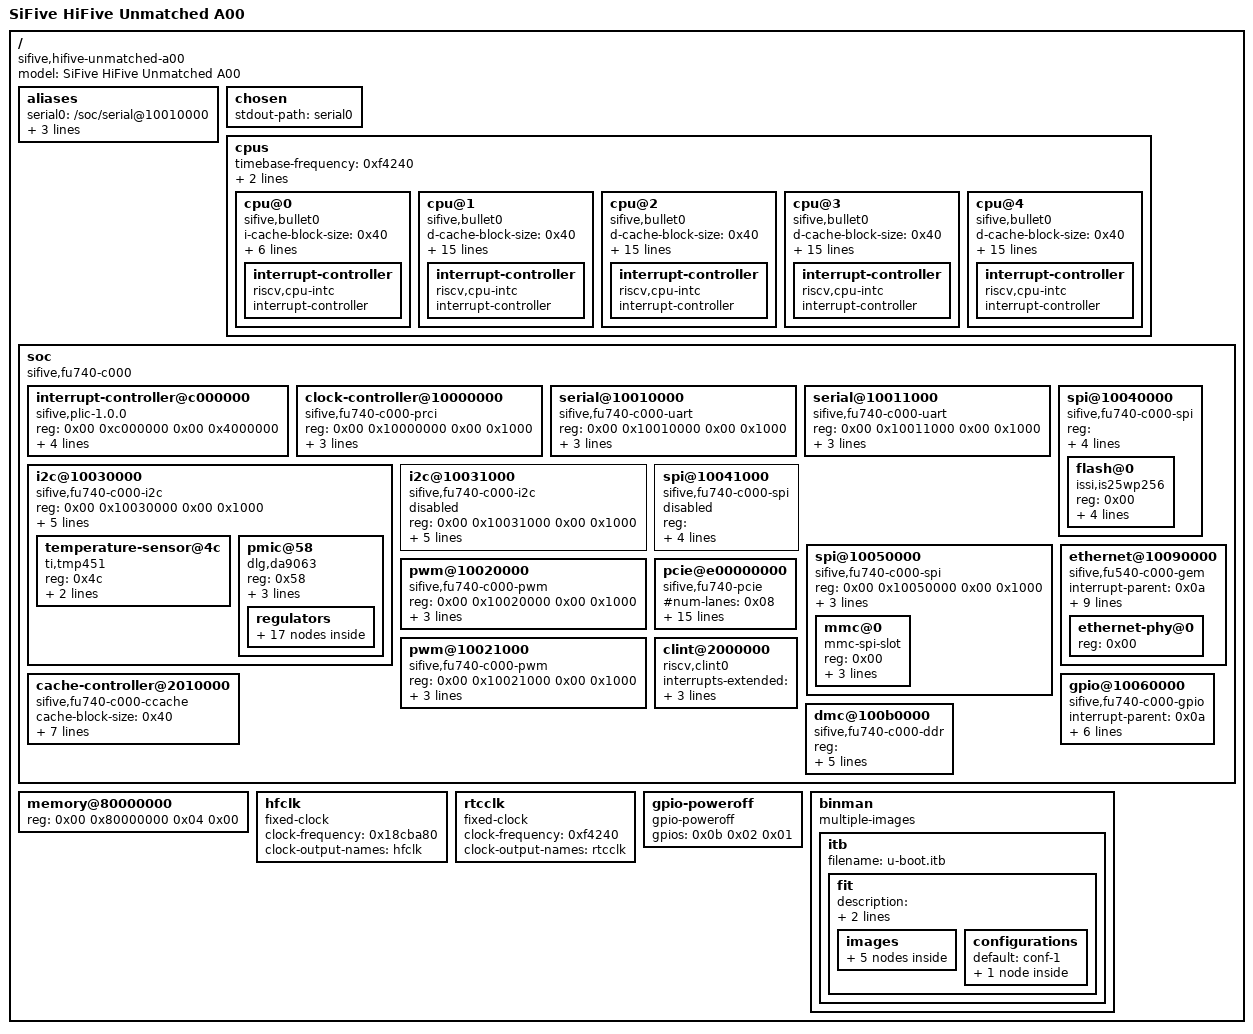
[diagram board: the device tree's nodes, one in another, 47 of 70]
/dts-v1/;

/ {
	#address-cells = <0x02>;
	#size-cells = <0x02>;
	compatible = "sifive,hifive-unmatched-a00\0sifive,fu740-c000\0sifive,fu740";
	model = "SiFive HiFive Unmatched A00";

	aliases {
		serial0 = "/soc/serial@10010000";
		serial1 = "/soc/serial@10011000";
		ethernet0 = "/soc/ethernet@10090000";
		spi0 = "/soc/spi@10050000";
	};

	chosen {
		stdout-path = "serial0";
	};

	cpus {
		#address-cells = <0x01>;
		#size-cells = <0x00>;
		timebase-frequency = <0xf4240>;
		assigned-clocks = <0x01 0x00>;
		assigned-clock-rates = <0x47868c00>;
		u-boot,dm-spl;

		cpu@0 {
			compatible = "sifive,bullet0\0riscv";
			device_type = "cpu";
			i-cache-block-size = <0x40>;
			i-cache-sets = <0x80>;
			i-cache-size = <0x4000>;
			next-level-cache = <0x02>;
			reg = <0x00>;
			riscv,isa = "rv64imac";
			status = "okay";
			clocks = <0x01 0x00>;
			u-boot,dm-spl;

			interrupt-controller {
				#interrupt-cells = <0x01>;
				compatible = "riscv,cpu-intc";
				interrupt-controller;
				u-boot,dm-spl;
				phandle = <0x03>;
			};
		};

		cpu@1 {
			compatible = "sifive,bullet0\0riscv";
			d-cache-block-size = <0x40>;
			d-cache-sets = <0x40>;
			d-cache-size = <0x8000>;
			d-tlb-sets = <0x01>;
			d-tlb-size = <0x28>;
			device_type = "cpu";
			i-cache-block-size = <0x40>;
			i-cache-sets = <0x80>;
			i-cache-size = <0x8000>;
			i-tlb-sets = <0x01>;
			i-tlb-size = <0x28>;
			mmu-type = "riscv,sv39";
			next-level-cache = <0x02>;
			reg = <0x01>;
			riscv,isa = "rv64imafdc";
			tlb-split;
			clocks = <0x01 0x00>;
			u-boot,dm-spl;

			interrupt-controller {
				#interrupt-cells = <0x01>;
				compatible = "riscv,cpu-intc";
				interrupt-controller;
				u-boot,dm-spl;
				phandle = <0x04>;
			};
		};

		cpu@2 {
			compatible = "sifive,bullet0\0riscv";
			d-cache-block-size = <0x40>;
			d-cache-sets = <0x40>;
			d-cache-size = <0x8000>;
			d-tlb-sets = <0x01>;
			d-tlb-size = <0x28>;
			device_type = "cpu";
			i-cache-block-size = <0x40>;
			i-cache-sets = <0x80>;
			i-cache-size = <0x8000>;
			i-tlb-sets = <0x01>;
			i-tlb-size = <0x28>;
			mmu-type = "riscv,sv39";
			next-level-cache = <0x02>;
			reg = <0x02>;
			riscv,isa = "rv64imafdc";
			tlb-split;
			clocks = <0x01 0x00>;
			u-boot,dm-spl;

			interrupt-controller {
				#interrupt-cells = <0x01>;
				compatible = "riscv,cpu-intc";
				interrupt-controller;
				u-boot,dm-spl;
				phandle = <0x05>;
			};
		};

		cpu@3 {
			compatible = "sifive,bullet0\0riscv";
			d-cache-block-size = <0x40>;
			d-cache-sets = <0x40>;
			d-cache-size = <0x8000>;
			d-tlb-sets = <0x01>;
			d-tlb-size = <0x28>;
			device_type = "cpu";
			i-cache-block-size = <0x40>;
			i-cache-sets = <0x80>;
			i-cache-size = <0x8000>;
			i-tlb-sets = <0x01>;
			i-tlb-size = <0x28>;
			mmu-type = "riscv,sv39";
			next-level-cache = <0x02>;
			reg = <0x03>;
			riscv,isa = "rv64imafdc";
			tlb-split;
			clocks = <0x01 0x00>;
			u-boot,dm-spl;

			interrupt-controller {
				#interrupt-cells = <0x01>;
				compatible = "riscv,cpu-intc";
				interrupt-controller;
				u-boot,dm-spl;
				phandle = <0x06>;
			};
		};

		cpu@4 {
			compatible = "sifive,bullet0\0riscv";
			d-cache-block-size = <0x40>;
			d-cache-sets = <0x40>;
			d-cache-size = <0x8000>;
			d-tlb-sets = <0x01>;
			d-tlb-size = <0x28>;
			device_type = "cpu";
			i-cache-block-size = <0x40>;
			i-cache-sets = <0x80>;
			i-cache-size = <0x8000>;
			i-tlb-sets = <0x01>;
			i-tlb-size = <0x28>;
			mmu-type = "riscv,sv39";
			next-level-cache = <0x02>;
			reg = <0x04>;
			riscv,isa = "rv64imafdc";
			tlb-split;
			clocks = <0x01 0x00>;
			u-boot,dm-spl;

			interrupt-controller {
				#interrupt-cells = <0x01>;
				compatible = "riscv,cpu-intc";
				interrupt-controller;
				u-boot,dm-spl;
				phandle = <0x07>;
			};
		};
	};

	soc {
		#address-cells = <0x02>;
		#size-cells = <0x02>;
		compatible = "sifive,fu740-c000\0sifive,fu740\0simple-bus";
		ranges;
		u-boot,dm-spl;

		interrupt-controller@c000000 {
			#interrupt-cells = <0x01>;
			compatible = "sifive,plic-1.0.0";
			reg = <0x00 0xc000000 0x00 0x4000000>;
			riscv,ndev = <0x45>;
			interrupt-controller;
			interrupts-extended = <0x03 0xffffffff 0x04 0xffffffff 0x04 0x09 0x05 0xffffffff 0x05 0x09 0x06 0xffffffff 0x06 0x09 0x07 0xffffffff 0x07 0x09>;
			phandle = <0x0a>;
		};

		clock-controller@10000000 {
			compatible = "sifive,fu740-c000-prci";
			reg = <0x00 0x10000000 0x00 0x1000>;
			clocks = <0x08 0x09>;
			#clock-cells = <0x01>;
			#reset-cells = <0x01>;
			resets = <0x01 0x00 0x01 0x01 0x01 0x02 0x01 0x03 0x01 0x05 0x01 0x06>;
			reset-names = "ddr_ctrl\0ddr_axi\0ddr_ahb\0ddr_phy\0gemgxl_reset\0cltx_reset";
			u-boot,dm-spl;
			phandle = <0x01>;
		};

		serial@10010000 {
			compatible = "sifive,fu740-c000-uart\0sifive,uart0";
			reg = <0x00 0x10010000 0x00 0x1000>;
			interrupt-parent = <0x0a>;
			interrupts = <0x27>;
			clocks = <0x01 0x07>;
			status = "okay";
			u-boot,dm-spl;
		};

		serial@10011000 {
			compatible = "sifive,fu740-c000-uart\0sifive,uart0";
			reg = <0x00 0x10011000 0x00 0x1000>;
			interrupt-parent = <0x0a>;
			interrupts = <0x28>;
			clocks = <0x01 0x07>;
			status = "okay";
		};

		i2c@10030000 {
			compatible = "sifive,fu740-c000-i2c\0sifive,i2c0";
			reg = <0x00 0x10030000 0x00 0x1000>;
			interrupt-parent = <0x0a>;
			interrupts = <0x34>;
			clocks = <0x01 0x07>;
			reg-shift = <0x02>;
			reg-io-width = <0x01>;
			#address-cells = <0x01>;
			#size-cells = <0x00>;
			status = "okay";
			u-boot,dm-spl;

			temperature-sensor@4c {
				compatible = "ti,tmp451";
				reg = <0x4c>;
				interrupt-parent = <0x0b>;
				interrupts = <0x06 0x08>;
			};

			pmic@58 {
				compatible = "dlg,da9063";
				reg = <0x58>;
				interrupt-parent = <0x0b>;
				interrupts = <0x01 0x08>;
				interrupt-controller;

				regulators {

					bcore1 {
						regulator-min-microvolt = <0x100590>;
						regulator-max-microvolt = <0x100590>;
						regulator-min-microamp = <0x4c4b40>;
						regulator-max-microamp = <0x4c4b40>;
						regulator-always-on;
					};

					bcore2 {
						regulator-min-microvolt = <0x100590>;
						regulator-max-microvolt = <0x100590>;
						regulator-min-microamp = <0x4c4b40>;
						regulator-max-microamp = <0x4c4b40>;
						regulator-always-on;
					};

					bpro {
						regulator-min-microvolt = <0x1b7740>;
						regulator-max-microvolt = <0x1b7740>;
						regulator-min-microamp = <0x2625a0>;
						regulator-max-microamp = <0x2625a0>;
						regulator-always-on;
					};

					bperi {
						regulator-min-microvolt = <0x100590>;
						regulator-max-microvolt = <0x100590>;
						regulator-min-microamp = <0x16e360>;
						regulator-max-microamp = <0x16e360>;
						regulator-always-on;
					};

					bmem {
						regulator-min-microvolt = <0x124f80>;
						regulator-max-microvolt = <0x124f80>;
						regulator-min-microamp = <0x2dc6c0>;
						regulator-max-microamp = <0x2dc6c0>;
						regulator-always-on;
					};

					bio {
						regulator-min-microvolt = <0x124f80>;
						regulator-max-microvolt = <0x124f80>;
						regulator-min-microamp = <0x2dc6c0>;
						regulator-max-microamp = <0x2dc6c0>;
						regulator-always-on;
					};

					ldo1 {
						regulator-min-microvolt = <0x1b7740>;
						regulator-max-microvolt = <0x1b7740>;
						regulator-min-microamp = <0x186a0>;
						regulator-max-microamp = <0x186a0>;
						regulator-always-on;
					};

					ldo2 {
						regulator-min-microvolt = <0x1b7740>;
						regulator-max-microvolt = <0x1b7740>;
						regulator-min-microamp = <0x30d40>;
						regulator-max-microamp = <0x30d40>;
						regulator-always-on;
					};

					ldo3 {
						regulator-min-microvolt = <0x325aa0>;
						regulator-max-microvolt = <0x325aa0>;
						regulator-min-microamp = <0x30d40>;
						regulator-max-microamp = <0x30d40>;
						regulator-always-on;
					};

					ldo4 {
						regulator-min-microvolt = <0x2625a0>;
						regulator-max-microvolt = <0x2625a0>;
						regulator-min-microamp = <0x30d40>;
						regulator-max-microamp = <0x30d40>;
						regulator-always-on;
					};

					ldo5 {
						regulator-min-microvolt = <0x325aa0>;
						regulator-max-microvolt = <0x325aa0>;
						regulator-min-microamp = <0x186a0>;
						regulator-max-microamp = <0x186a0>;
						regulator-always-on;
					};

					ldo6 {
						regulator-min-microvolt = <0x1b7740>;
						regulator-max-microvolt = <0x1b7740>;
						regulator-min-microamp = <0x30d40>;
						regulator-max-microamp = <0x30d40>;
						regulator-always-on;
					};

					ldo7 {
						regulator-min-microvolt = <0x325aa0>;
						regulator-max-microvolt = <0x325aa0>;
						regulator-min-microamp = <0x30d40>;
						regulator-max-microamp = <0x30d40>;
						regulator-always-on;
					};

					ldo8 {
						regulator-min-microvolt = <0x325aa0>;
						regulator-max-microvolt = <0x325aa0>;
						regulator-min-microamp = <0x30d40>;
						regulator-max-microamp = <0x30d40>;
						regulator-always-on;
					};

					ldo9 {
						regulator-min-microvolt = <0x100590>;
						regulator-max-microvolt = <0x100590>;
						regulator-min-microamp = <0x30d40>;
						regulator-max-microamp = <0x30d40>;
					};

					ldo10 {
						regulator-min-microvolt = <0xf4240>;
						regulator-max-microvolt = <0xf4240>;
						regulator-min-microamp = <0x493e0>;
						regulator-max-microamp = <0x493e0>;
					};

					ldo11 {
						regulator-min-microvolt = <0x2625a0>;
						regulator-max-microvolt = <0x2625a0>;
						regulator-min-microamp = <0x493e0>;
						regulator-max-microamp = <0x493e0>;
						regulator-always-on;
					};
				};
			};
		};

		i2c@10031000 {
			compatible = "sifive,fu740-c000-i2c\0sifive,i2c0";
			reg = <0x00 0x10031000 0x00 0x1000>;
			interrupt-parent = <0x0a>;
			interrupts = <0x35>;
			clocks = <0x01 0x07>;
			reg-shift = <0x02>;
			reg-io-width = <0x01>;
			#address-cells = <0x01>;
			#size-cells = <0x00>;
			status = "disabled";
		};

		spi@10040000 {
			compatible = "sifive,fu740-c000-spi\0sifive,spi0";
			reg = <0x00 0x10040000 0x00 0x1000 0x00 0x20000000 0x00 0x10000000>;
			interrupt-parent = <0x0a>;
			interrupts = <0x29>;
			clocks = <0x01 0x07>;
			#address-cells = <0x01>;
			#size-cells = <0x00>;
			status = "okay";

			flash@0 {
				compatible = "issi,is25wp256\0jedec,spi-nor";
				reg = <0x00>;
				spi-max-frequency = <0x2faf080>;
				m25p,fast-read;
				spi-tx-bus-width = <0x04>;
				spi-rx-bus-width = <0x04>;
			};
		};

		spi@10041000 {
			compatible = "sifive,fu740-c000-spi\0sifive,spi0";
			reg = <0x00 0x10041000 0x00 0x1000 0x00 0x30000000 0x00 0x10000000>;
			interrupt-parent = <0x0a>;
			interrupts = <0x2a>;
			clocks = <0x01 0x07>;
			#address-cells = <0x01>;
			#size-cells = <0x00>;
			status = "disabled";
		};

		spi@10050000 {
			compatible = "sifive,fu740-c000-spi\0sifive,spi0";
			reg = <0x00 0x10050000 0x00 0x1000>;
			interrupt-parent = <0x0a>;
			interrupts = <0x2b>;
			clocks = <0x01 0x07>;
			#address-cells = <0x01>;
			#size-cells = <0x00>;
			status = "okay";
			u-boot,dm-spl;

			mmc@0 {
				compatible = "mmc-spi-slot";
				reg = <0x00>;
				spi-max-frequency = <0x1312d00>;
				voltage-ranges = <0xce4 0xce4>;
				disable-wp;
				u-boot,dm-spl;
			};
		};

		ethernet@10090000 {
			compatible = "sifive,fu540-c000-gem";
			interrupt-parent = <0x0a>;
			interrupts = <0x37>;
			reg = <0x00 0x10090000 0x00 0x2000 0x00 0x100a0000 0x00 0x1000>;
			local-mac-address = [00 00 00 00 00 00];
			clock-names = "pclk\0hclk";
			clocks = <0x01 0x02 0x01 0x02>;
			#address-cells = <0x01>;
			#size-cells = <0x00>;
			status = "okay";
			phy-mode = "gmii";
			phy-handle = <0x0c>;
			assigned-clocks = <0x01 0x02>;
			assigned-clock-rates = <0x7754188>;

			ethernet-phy@0 {
				reg = <0x00>;
				phandle = <0x0c>;
			};
		};

		pwm@10020000 {
			compatible = "sifive,fu740-c000-pwm\0sifive,pwm0";
			reg = <0x00 0x10020000 0x00 0x1000>;
			interrupt-parent = <0x0a>;
			interrupts = <0x2c 0x2d 0x2e 0x2f>;
			clocks = <0x01 0x07>;
			#pwm-cells = <0x03>;
			status = "okay";
		};

		pwm@10021000 {
			compatible = "sifive,fu740-c000-pwm\0sifive,pwm0";
			reg = <0x00 0x10021000 0x00 0x1000>;
			interrupt-parent = <0x0a>;
			interrupts = <0x30 0x31 0x32 0x33>;
			clocks = <0x01 0x07>;
			#pwm-cells = <0x03>;
			status = "okay";
		};

		cache-controller@2010000 {
			compatible = "sifive,fu740-c000-ccache\0cache";
			cache-block-size = <0x40>;
			cache-level = <0x02>;
			cache-sets = <0x800>;
			cache-size = <0x200000>;
			cache-unified;
			interrupt-parent = <0x0a>;
			interrupts = <0x13 0x15 0x16 0x14>;
			reg = <0x00 0x2010000 0x00 0x1000>;
			status = "okay";
			phandle = <0x02>;
		};

		gpio@10060000 {
			compatible = "sifive,fu740-c000-gpio\0sifive,gpio0";
			interrupt-parent = <0x0a>;
			interrupts = <0x17 0x18 0x19 0x1a 0x1b 0x1c 0x1d 0x1e 0x1f 0x20 0x21 0x22 0x23 0x24 0x25 0x26>;
			reg = <0x00 0x10060000 0x00 0x1000>;
			gpio-controller;
			#gpio-cells = <0x02>;
			interrupt-controller;
			#interrupt-cells = <0x02>;
			clocks = <0x01 0x07>;
			status = "okay";
			u-boot,dm-spl;
			phandle = <0x0b>;
		};

		pcie@e00000000 {
			#address-cells = <0x03>;
			#interrupt-cells = <0x01>;
			#num-lanes = <0x08>;
			#size-cells = <0x02>;
			compatible = "sifive,fu740-pcie";
			reg = <0x0e 0x00 0x01 0x00 0x0d 0xf0000000 0x00 0x10000000 0x00 0x100d0000 0x00 0x1000>;
			reg-names = "dbi\0config\0mgmt";
			device_type = "pci";
			dma-coherent;
			bus-range = <0x00 0xff>;
			ranges = <0x81000000 0x00 0x60080000 0x00 0x60080000 0x00 0x10000 0x82000000 0x00 0x60090000 0x00 0x60090000 0x00 0xff70000 0x82000000 0x00 0x70000000 0x00 0x70000000 0x00 0x1000000 0xc3000000 0x20 0x00 0x20 0x00 0x20 0x00>;
			num-lanes = <0x08>;
			interrupts = <0x38 0x39 0x3a 0x3b 0x3c 0x3d 0x3e 0x3f 0x40>;
			interrupt-names = "msi\0inta\0intb\0intc\0intd";
			interrupt-parent = <0x0a>;
			interrupt-map-mask = <0x00 0x00 0x00 0x07>;
			interrupt-map = <0x00 0x00 0x00 0x01 0x0a 0x39 0x00 0x00 0x00 0x02 0x0a 0x3a 0x00 0x00 0x00 0x03 0x0a 0x3b 0x00 0x00 0x00 0x04 0x0a 0x3c>;
			pwren-gpios = <0x0b 0x05 0x00>;
			reset-gpios = <0x0b 0x08 0x00>;
			clocks = <0x01 0x08>;
			clock-names = "pcieaux";
			resets = <0x01 0x04>;
			reset-names = "rst_n";
			status = "okay";
		};

		clint@2000000 {
			compatible = "riscv,clint0";
			interrupts-extended = <0x03 0x03 0x03 0x07 0x04 0x03 0x04 0x07 0x05 0x03 0x05 0x07 0x06 0x03 0x06 0x07 0x07 0x03 0x07 0x07>;
			reg = <0x00 0x2000000 0x00 0x10000>;
			u-boot,dm-spl;
			clocks = <0x09>;
		};

		dmc@100b0000 {
			compatible = "sifive,fu740-c000-ddr";
			reg = <0x00 0x100b0000 0x00 0x800 0x00 0x100b2000 0x00 0x2000 0x00 0x100b8000 0x00 0x1000>;
			clocks = <0x01 0x01>;
			clock-frequency = <0x37a1894c>;
			u-boot,dm-spl;
			sifive,ddr-params = <0xa00 0x00 0x00 0x00 0x00 0x00 0x0a 0x2d362 0x71073 0xa1c0255 0x1c1c0400 0x404c90b 0x2b050405 0xd0c081e 0x8090914 0xfde718 0x180a05 0x8b130d 0x1000118 0xd032001 0x00 0x101 0x00 0xa000000 0x00 0x1450100 0x1c36 0x05 0x170006 0x14e0400 0x3010000 0xa0e00 0x4030200 0x31f 0x70004 0x00 0x00 0x00 0x00 0x00 0x00 0x00 0x00 0x00 0x00 0x00 0x00 0x00 0x00 0x00 0x00 0x00 0x00 0x00 0x00 0x00 0x00 0x00 0x00 0x00 0x424 0x201 0x1008 0x00 0x200 0x800 0x481 0x400 0x424 0x201 0x1008 0x00 0x200 0x800 0x481 0x400 0x1010000 0x00 0x00 0x00 0x00 0x00 0x00 0x00 0x00 0x00 0x00 0x00 0x00 0x00 0x00 0x00 0x00 0x00 0x00 0x00 0x00 0x00 0x00 0x00 0x00 0x00 0x00 0x00 0x00 0x03 0x00 0x00 0x00 0x00 0x1000000 0x40000 0x800200 0x200 0x40 0x1000100 0xa000002 0x101ffff 0x1010101 0x1010101 0x10b 0xc03 0x00 0x00 0x00 0x00 0x30300 0x00 0x10101 0x00 0x00 0x00 0x00 0x00 0x00 0x00 0x00 0x00 0x00 0x00 0x00 0x00 0x00 0x00 0x00 0x00 0x00 0x00 0x00 0x00 0x00 0x00 0x00 0x00 0x00 0x00 0x00 0x00 0x00 0x00 0x00 0x2010102 0x108070d 0x5050300 0x4000503 0x00 0x00 0x00 0x00 0x280d0000 0x1000000 0x00 0x30001 0x00 0x00 0x00 0x00 0x00 0x00 0x00 0x00 0x1000000 0x01 0x100 0x10303 0x67676701 0x67676767 0x67676767 0x67676767 0x67676767 0x67676767 0x67676767 0x67676767 0x67676767 0x1000067 0x01 0x101 0x00 0x00 0x00 0x00 0x00 0x00 0x00 0x00 0x00 0x00 0x00 0x01 0x00 0x7fffff 0x00 0x7fffff 0x00 0x7fffff 0x00 0x7fffff 0x00 0x7fffff 0x00 0x7fffff 0x00 0x7fffff 0x00 0x37fffff 0xffffffff 0xf000f 0xffff03 0xfffff 0x3000f 0xffffffff 0xf000f 0xffff03 0xfffff 0x3000f 0xffffffff 0xf000f 0xffff03 0xfffff 0x3000f 0xffffffff 0xf000f 0xffff03 0xfffff 0x6407000f 0x1640001 0x00 0x00 0x1800 0x386c05 0x2000200 0x2000200 0x386c 0x23438 0x2020d0f 0x140303 0x00 0x00 0x1403 0x00 0x00 0x00 0x00 0xc010000 0x08 0x1375642 0x4c008 0xda 0x00 0x00 0x10000 0x1dddd90 0x1dddd90 0x1030001 0x1000000 0xc00000 0x07 0x00 0x00 0x4000408 0x408 0xe4e400 0x00 0x00 0x00 0x00 0x00 0x00 0x00 0x00 0x00 0x00 0x00 0x00 0x00 0x00 0x00 0x00 0x200000 0x00 0x00 0x00 0x00 0x00 0x00 0x2800280 0x2800280 0x2800280 0x2800280 0x280 0x00 0x00 0x00 0x00 0x00 0x800080 0x800080 0x800080 0x800080 0x800080 0x800080 0x800080 0x800080 0x800080 0x100da 0x1ff0010 0x00 0x00 0x02 0x51313152 0x80013130 0x2000080 0x100001 0xc064208 0xf0c0f 0x1000140 0x0c 0x00 0x00 0x00 0x00 0x00 0x00 0x00 0x00 0x00 0x00 0x00 0x00 0x00 0x00 0x00 0x00 0x00 0x00 0x00 0x00 0x00 0x00 0x00 0x00 0x00 0x00 0x00 0x00 0x00 0x00 0x00 0x00 0x00 0x00 0x00 0x00 0x00 0x00 0x00 0x00 0x00 0x00 0x00 0x00 0x00 0x00 0x00 0x00 0x00 0x00 0x00 0x00 0x00 0x00 0x00 0x00 0x40263571 0x4c008 0xda 0x00 0x00 0x10000 0x1dddd90 0x1dddd90 0x1030001 0x1000000 0xc00000 0x07 0x00 0x00 0x4000408 0x408 0xe4e400 0x00 0x00 0x00 0x00 0x00 0x00 0x00 0x00 0x00 0x00 0x00 0x00 0x00 0x00 0x00 0x00 0x200000 0x00 0x00 0x00 0x00 0x00 0x00 0x2800280 0x2800280 0x2800280 0x2800280 0x280 0x00 0x00 0x00 0x00 0x00 0x800080 0x800080 0x800080 0x800080 0x800080 0x800080 0x800080 0x800080 0x800080 0x100da 0x1ff0010 0x00 0x00 0x02 0x51313152 0x80013130 0x2000080 0x100001 0xc064208 0xf0c0f 0x1000140 0x0c 0x00 0x00 0x00 0x00 0x00 0x00 0x00 0x00 0x00 0x00 0x00 0x00 0x00 0x00 0x00 0x00 0x00 0x00 0x00 0x00 0x00 0x00 0x00 0x00 0x00 0x00 0x00 0x00 0x00 0x00 0x00 0x00 0x00 0x00 0x00 0x00 0x00 0x00 0x00 0x00 0x00 0x00 0x00 0x00 0x00 0x00 0x00 0x00 0x00 0x00 0x00 0x00 0x00 0x00 0x00 0x00 0x46052371 0x4c008 0xda 0x00 0x00 0x10000 0x1dddd90 0x1dddd90 0x1030001 0x1000000 0xc00000 0x07 0x00 0x00 0x4000408 0x408 0xe4e400 0x00 0x00 0x00 0x00 0x00 0x00 0x00 0x00 0x00 0x00 0x00 0x00 0x00 0x00 0x00 0x00 0x200000 0x00 0x00 0x00 0x00 0x00 0x00 0x2800280 0x2800280 0x2800280 0x2800280 0x280 0x00 0x00 0x00 0x00 0x00 0x800080 0x800080 0x800080 0x800080 0x800080 0x800080 0x800080 0x800080 0x800080 0x100da 0x1ff0010 0x00 0x00 0x02 0x51313152 0x80013130 0x2000080 0x100001 0xc064208 0xf0c0f 0x1000140 0x0c 0x00 0x00 0x00 0x00 0x00 0x00 0x00 0x00 0x00 0x00 0x00 0x00 0x00 0x00 0x00 0x00 0x00 0x00 0x00 0x00 0x00 0x00 0x00 0x00 0x00 0x00 0x00 0x00 0x00 0x00 0x00 0x00 0x00 0x00 0x00 0x00 0x00 0x00 0x00 0x00 0x00 0x00 0x00 0x00 0x00 0x00 0x00 0x00 0x00 0x00 0x00 0x00 0x00 0x00 0x00 0x00 0x37651240 0x4c008 0xda 0x00 0x00 0x10000 0x1dddd90 0x1dddd90 0x1030001 0x1000000 0xc00000 0x07 0x00 0x00 0x4000408 0x408 0xe4e400 0x00 0x00 0x00 0x00 0x00 0x00 0x00 0x00 0x00 0x00 0x00 0x00 0x00 0x00 0x00 0x00 0x200000 0x00 0x00 0x00 0x00 0x00 0x00 0x2800280 0x2800280 0x2800280 0x2800280 0x280 0x00 0x00 0x00 0x00 0x00 0x800080 0x800080 0x800080 0x800080 0x800080 0x800080 0x800080 0x800080 0x800080 0x100da 0x1ff0010 0x00 0x00 0x02 0x51313152 0x80013130 0x2000080 0x100001 0xc064208 0xf0c0f 0x1000140 0x0c 0x00 0x00 0x00 0x00 0x00 0x00 0x00 0x00 0x00 0x00 0x00 0x00 0x00 0x00 0x00 0x00 0x00 0x00 0x00 0x00 0x00 0x00 0x00 0x00 0x00 0x00 0x00 0x00 0x00 0x00 0x00 0x00 0x00 0x00 0x00 0x00 0x00 0x00 0x00 0x00 0x00 0x00 0x00 0x00 0x00 0x00 0x00 0x00 0x00 0x00 0x00 0x00 0x00 0x00 0x00 0x00 0x34216750 0x4c008 0xda 0x00 0x00 0x10000 0x1dddd90 0x1dddd90 0x1030001 0x1000000 0xc00000 0x07 0x00 0x00 0x4000408 0x408 0xe4e400 0x00 0x00 0x00 0x00 0x00 0x00 0x00 0x00 0x00 0x00 0x00 0x00 0x00 0x00 0x00 0x00 0x200000 0x00 0x00 0x00 0x00 0x00 0x00 0x2800280 0x2800280 0x2800280 0x2800280 0x280 0x00 0x00 0x00 0x00 0x00 0x800080 0x800080 0x800080 0x800080 0x800080 0x800080 0x800080 0x800080 0x800080 0x100da 0x1ff0010 0x00 0x00 0x02 0x51313152 0x80013130 0x2000080 0x100001 0xc064208 0xf0c0f 0x1000140 0x0c 0x00 0x00 0x00 0x00 0x00 0x00 0x00 0x00 0x00 0x00 0x00 0x00 0x00 0x00 0x00 0x00 0x00 0x00 0x00 0x00 0x00 0x00 0x00 0x00 0x00 0x00 0x00 0x00 0x00 0x00 0x00 0x00 0x00 0x00 0x00 0x00 0x00 0x00 0x00 0x00 0x00 0x00 0x00 0x00 0x00 0x00 0x00 0x00 0x00 0x00 0x00 0x00 0x00 0x00 0x00 0x00 0x35176402 0x4c008 0xda 0x00 0x00 0x10000 0x1dddd90 0x1dddd90 0x1030001 0x1000000 0xc00000 0x07 0x00 0x00 0x4000408 0x408 0xe4e400 0x00 0x00 0x00 0x00 0x00 0x00 0x00 0x00 0x00 0x00 0x00 0x00 0x00 0x00 0x00 0x00 0x200000 0x00 0x00 0x00 0x00 0x00 0x00 0x2800280 0x2800280 0x2800280 0x2800280 0x280 0x00 0x00 0x00 0x00 0x00 0x800080 0x800080 0x800080 0x800080 0x800080 0x800080 0x800080 0x800080 0x800080 0x100da 0x1ff0010 0x00 0x00 0x02 0x51313152 0x80013130 0x2000080 0x100001 0xc064208 0xf0c0f 0x1000140 0x0c 0x00 0x00 0x00 0x00 0x00 0x00 0x00 0x00 0x00 0x00 0x00 0x00 0x00 0x00 0x00 0x00 0x00 0x00 0x00 0x00 0x00 0x00 0x00 0x00 0x00 0x00 0x00 0x00 0x00 0x00 0x00 0x00 0x00 0x00 0x00 0x00 0x00 0x00 0x00 0x00 0x00 0x00 0x00 0x00 0x00 0x00 0x00 0x00 0x00 0x00 0x00 0x00 0x00 0x00 0x00 0x00 0x10526347 0x4c008 0xda 0x00 0x00 0x10000 0x1dddd90 0x1dddd90 0x1030001 0x1000000 0xc00000 0x07 0x00 0x00 0x4000408 0x408 0xe4e400 0x00 0x00 0x00 0x00 0x00 0x00 0x00 0x00 0x00 0x00 0x00 0x00 0x00 0x00 0x00 0x00 0x200000 0x00 0x00 0x00 0x00 0x00 0x00 0x2800280 0x2800280 0x2800280 0x2800280 0x280 0x00 0x00 0x00 0x00 0x00 0x800080 0x800080 0x800080 0x800080 0x800080 0x800080 0x800080 0x800080 0x800080 0x100da 0x1ff0010 0x00 0x00 0x02 0x51313152 0x80013130 0x2000080 0x100001 0xc064208 0xf0c0f 0x1000140 0x0c 0x00 0x00 0x00 0x00 0x00 0x00 0x00 0x00 0x00 0x00 0x00 0x00 0x00 0x00 0x00 0x00 0x00 0x00 0x00 0x00 0x00 0x00 0x00 0x00 0x00 0x00 0x00 0x00 0x00 0x00 0x00 0x00 0x00 0x00 0x00 0x00 0x00 0x00 0x00 0x00 0x00 0x00 0x00 0x00 0x00 0x00 0x00 0x00 0x00 0x00 0x00 0x00 0x00 0x00 0x00 0x00 0x41753260 0x4c008 0xda 0x00 0x00 0x10000 0x1dddd90 0x1dddd90 0x1030001 0x1000000 0xc00000 0x07 0x00 0x00 0x4000408 0x408 0xe4e400 0x00 0x00 0x00 0x00 0x00 0x00 0x00 0x00 0x00 0x00 0x00 0x00 0x00 0x00 0x00 0x00 0x200000 0x00 0x00 0x00 0x00 0x00 0x00 0x2800280 0x2800280 0x2800280 0x2800280 0x280 0x00 0x00 0x00 0x00 0x00 0x800080 0x800080 0x800080 0x800080 0x800080 0x800080 0x800080 0x800080 0x800080 0x100da 0x1ff0010 0x00 0x00 0x02 0x51313152 0x80013130 0x2000080 0x100001 0xc064208 0xf0c0f 0x1000140 0x0c 0x00 0x00 0x00 0x00 0x00 0x00 0x00 0x00 0x00 0x00 0x00 0x00 0x00 0x00 0x00 0x00 0x00 0x00 0x00 0x00 0x00 0x00 0x00 0x00 0x00 0x00 0x00 0x00 0x00 0x00 0x00 0x00 0x00 0x00 0x00 0x00 0x00 0x00 0x00 0x00 0x00 0x00 0x00 0x00 0x00 0x00 0x00 0x00 0x00 0x00 0x00 0x00 0x00 0x00 0x00 0x00 0x76543210 0x4c008 0xda 0x00 0x00 0x10000 0x1665555 0x1665555 0x1030001 0x1000000 0xc00000 0x07 0x00 0x00 0x4000408 0x408 0xe4e400 0x00 0x00 0x00 0x00 0x00 0x00 0x00 0x00 0x00 0x00 0x00 0x00 0x00 0x00 0x00 0x00 0x200000 0x00 0x00 0x00 0x00 0x00 0x00 0x2800280 0x2800280 0x2800280 0x2800280 0x280 0x00 0x00 0x00 0x00 0x00 0x800080 0x800080 0x800080 0x800080 0x800080 0x800080 0x800080 0x800080 0x800080 0x100da 0x1ff0010 0x00 0x00 0x02 0x51313152 0x80013130 0x2000080 0x100001 0xc064208 0xf0c0f 0x1000140 0x0c 0x00 0x00 0x00 0x00 0x00 0x00 0x00 0x00 0x00 0x00 0x00 0x00 0x00 0x00 0x00 0x00 0x00 0x00 0x00 0x00 0x00 0x00 0x00 0x00 0x00 0x00 0x00 0x00 0x00 0x00 0x00 0x00 0x00 0x00 0x00 0x00 0x00 0x00 0x00 0x00 0x00 0x00 0x00 0x00 0x00 0x00 0x00 0x00 0x00 0x00 0x00 0x00 0x00 0x00 0x00 0x00 0x00 0x00 0x50000 0x00 0x00 0x00 0x100 0x00 0x00 0x506401 0x1221102 0x122 0x00 0xb1f00 0xb1f0b1f 0xb1f0b1f 0xb1f0b1f 0xb1f0b1f 0xb00 0x42080010 0x1000100 0x1000100 0x1000100 0x1000100 0x00 0x00 0x00 0x00 0x00 0x803 0x223fff00 0x8ff 0x57f 0x57f 0x37fff 0x37fff 0x4410 0x4410 0x4410 0x4410 0x4410 0x111 0x111 0x00 0x00 0x00 0x4000000 0x00 0x00 0x108 0x00 0x00 0x00 0x01 0x00 0x00 0x00 0x00 0x00 0x00 0x20100 0x00 0x00>;
		};
	};

	memory@80000000 {
		device_type = "memory";
		reg = <0x00 0x80000000 0x04 0x00>;
		u-boot,dm-spl;
	};

	hfclk {
		#clock-cells = <0x00>;
		compatible = "fixed-clock";
		clock-frequency = <0x18cba80>;
		clock-output-names = "hfclk";
		u-boot,dm-spl;
		phandle = <0x08>;
	};

	rtcclk {
		#clock-cells = <0x00>;
		compatible = "fixed-clock";
		clock-frequency = <0xf4240>;
		clock-output-names = "rtcclk";
		u-boot,dm-spl;
		phandle = <0x09>;
	};

	gpio-poweroff {
		compatible = "gpio-poweroff";
		gpios = <0x0b 0x02 0x01>;
	};

	binman {
		multiple-images;

		itb {
			filename = "u-boot.itb";

			fit {
				description = "Configuration to load OpenSBI before U-Boot";
				#address-cells = <0x01>;
				fit,fdt-list = "of-list";

				images {

					uboot {
						description = "U-Boot";
						type = "standalone";
						os = "U-Boot";
						arch = "riscv";
						compression = "none";
						load = <0x80200000>;

						blob-ext {
							filename = "u-boot-nodtb.bin";
						};
					};

					opensbi {
						description = "OpenSBI fw_dynamic Firmware";
						type = "firmware";
						os = "opensbi";
						arch = "riscv";
						compression = "none";
						load = <0x80000000>;
						entry = <0x80000000>;

						opensbi {
							filename = "fw_dynamic.bin";
						};
					};

					@fdt-SEQ {
						description = "NAME";
						type = "flat_dt";
						compression = "none";
					};
				};

				configurations {
					default = "conf-1";

					@conf-SEQ {
						description = "NAME";
						firmware = "opensbi";
						loadables = "uboot";
						fdt = "fdt-SEQ";
					};
				};
			};
		};
	};
};
